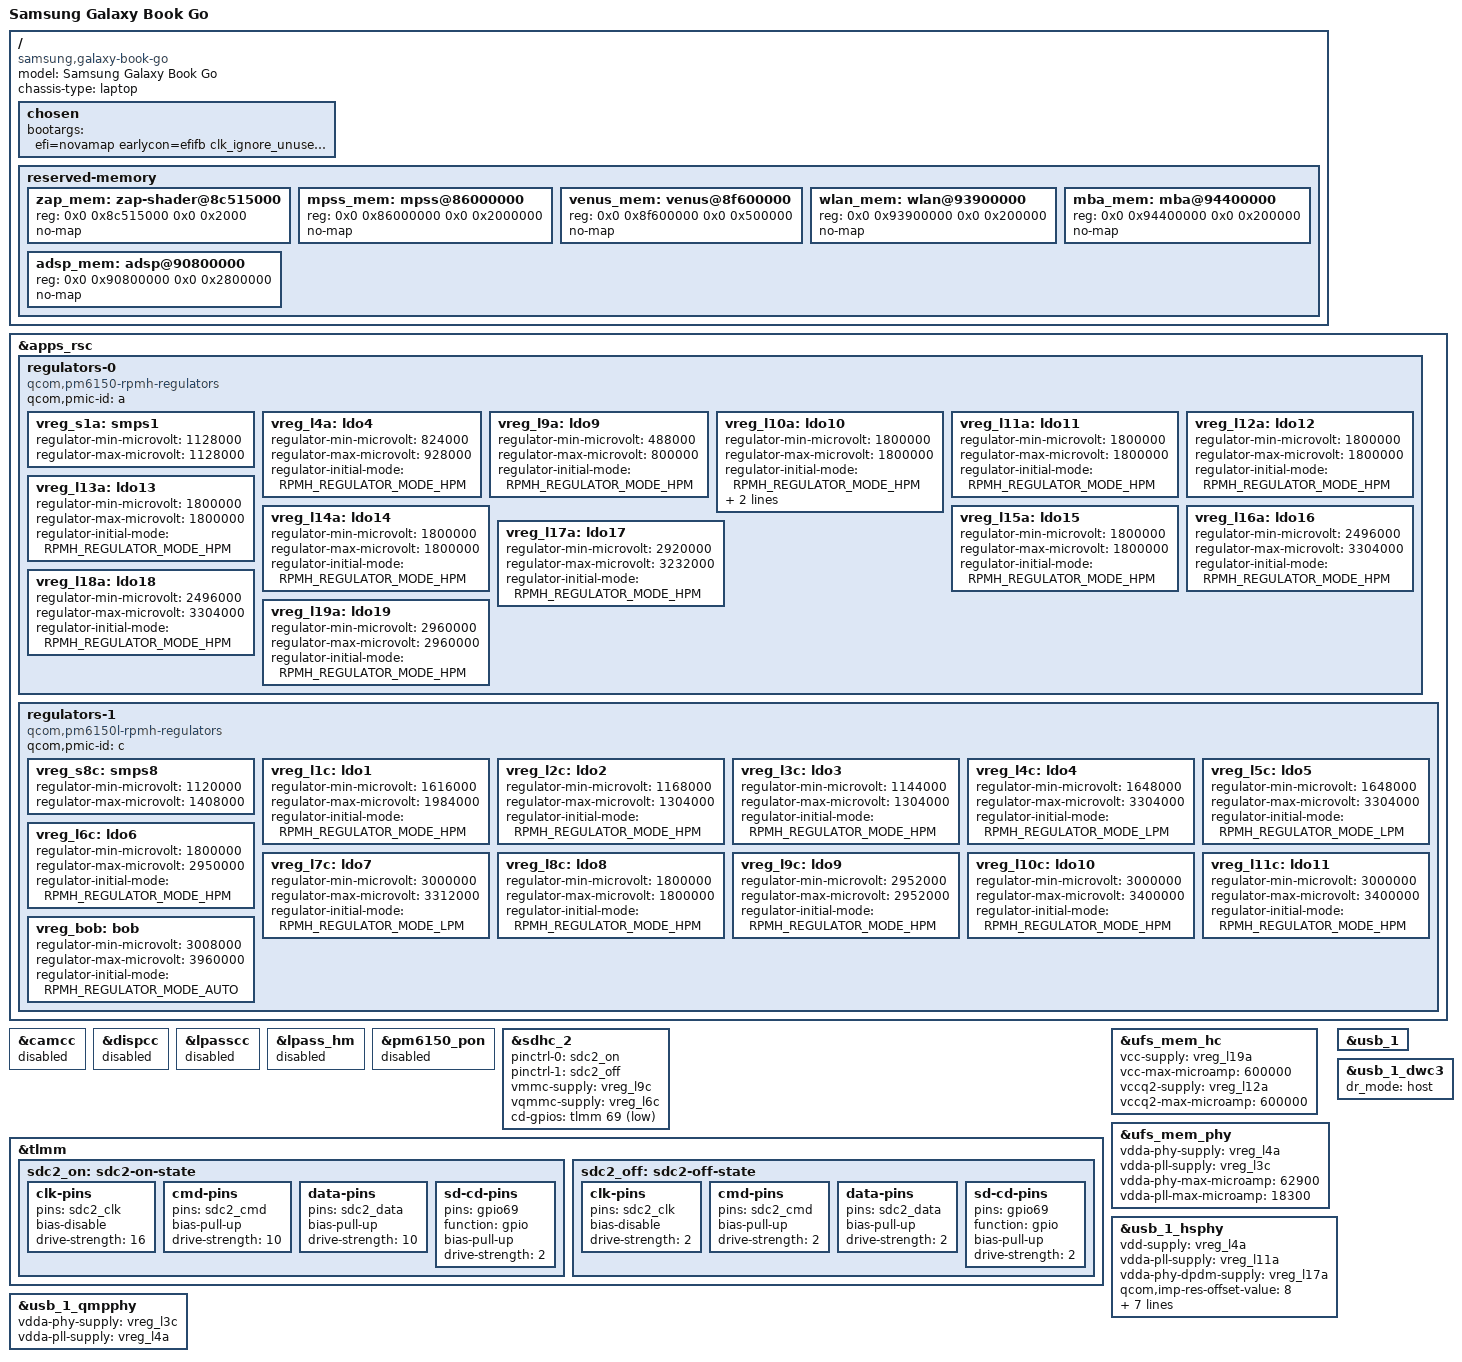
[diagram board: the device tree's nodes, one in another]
// SPDX-License-Identifier: BSD-3-Clause

/dts-v1/;

#include <dt-bindings/gpio/gpio.h>
#include <dt-bindings/regulator/qcom,rpmh-regulator.h>
#include "sc7180.dtsi"
#include "pm6150.dtsi"
#include "pm6150l.dtsi"

/ {
	model = "Samsung Galaxy Book Go";
	compatible = "samsung,galaxy-book-go", "qcom,sc7180";
	chassis-type = "laptop";

	chosen {
		bootargs = "efi=novamap earlycon=efifb clk_ignore_unused pd_ignore_unused console=efifb";
	};

	reserved-memory {
		zap_mem: zap-shader@8c515000 {
			reg = <0x0 0x8c515000 0x0 0x2000>;
			no-map;
		};

		mpss_mem: mpss@86000000 {
			reg = <0x0 0x86000000 0x0 0x2000000>;
			no-map;
		};

		venus_mem: venus@8f600000 {
			reg = <0x0 0x8f600000 0x0 0x500000>;
			no-map;
		};

		wlan_mem: wlan@93900000 {
			reg = <0x0 0x93900000 0x0 0x200000>;
			no-map;
		};

		mba_mem: mba@94400000 {
			reg = <0x0 0x94400000 0x0 0x200000>;
			no-map;
		};

		adsp_mem: adsp@90800000 {
			reg = <0x0 0x90800000 0x0 0x2800000>;
			no-map;
		};
	};
};

&apps_rsc {
	regulators-0 {
		compatible = "qcom,pm6150-rpmh-regulators";
		qcom,pmic-id = "a";

		vreg_s1a: smps1 {
			regulator-min-microvolt = <1128000>;
			regulator-max-microvolt = <1128000>;
		};

		vreg_l4a: ldo4 {
			regulator-min-microvolt = <824000>;
			regulator-max-microvolt = <928000>;
			regulator-initial-mode = <RPMH_REGULATOR_MODE_HPM>;
		};

		vreg_l9a: ldo9 {
			regulator-min-microvolt = <488000>;
			regulator-max-microvolt = <800000>;
			regulator-initial-mode = <RPMH_REGULATOR_MODE_HPM>;
		};

		vreg_l10a: ldo10 {
			regulator-min-microvolt = <1800000>;
			regulator-max-microvolt = <1800000>;
			regulator-initial-mode = <RPMH_REGULATOR_MODE_HPM>;

			regulator-always-on;
			regulator-boot-on;
		};

		vreg_l11a: ldo11 {
			regulator-min-microvolt = <1800000>;
			regulator-max-microvolt = <1800000>;
			regulator-initial-mode = <RPMH_REGULATOR_MODE_HPM>;
		};

		vreg_l12a: ldo12 {
			regulator-min-microvolt = <1800000>;
			regulator-max-microvolt = <1800000>;
			regulator-initial-mode = <RPMH_REGULATOR_MODE_HPM>;
		};

		vreg_l13a: ldo13 {
			regulator-min-microvolt = <1800000>;
			regulator-max-microvolt = <1800000>;
			regulator-initial-mode = <RPMH_REGULATOR_MODE_HPM>;
		};

		vreg_l14a: ldo14 {
			regulator-min-microvolt = <1800000>;
			regulator-max-microvolt = <1800000>;
			regulator-initial-mode = <RPMH_REGULATOR_MODE_HPM>;
		};

		vreg_l15a: ldo15 {
			regulator-min-microvolt = <1800000>;
			regulator-max-microvolt = <1800000>;
			regulator-initial-mode = <RPMH_REGULATOR_MODE_HPM>;
		};

		vreg_l16a: ldo16 {
			regulator-min-microvolt = <2496000>;
			regulator-max-microvolt = <3304000>;
			regulator-initial-mode = <RPMH_REGULATOR_MODE_HPM>;
		};

		vreg_l17a: ldo17 {
			regulator-min-microvolt = <2920000>;
			regulator-max-microvolt = <3232000>;
			regulator-initial-mode = <RPMH_REGULATOR_MODE_HPM>;
		};

		vreg_l18a: ldo18 {
			regulator-min-microvolt = <2496000>;
			regulator-max-microvolt = <3304000>;
			regulator-initial-mode = <RPMH_REGULATOR_MODE_HPM>;
		};

		vreg_l19a: ldo19 {
			regulator-min-microvolt = <2960000>;
			regulator-max-microvolt = <2960000>;
			regulator-initial-mode = <RPMH_REGULATOR_MODE_HPM>;
		};
	};

	regulators-1 {
		compatible = "qcom,pm6150l-rpmh-regulators";
		qcom,pmic-id = "c";

		vreg_s8c: smps8 {
			regulator-min-microvolt = <1120000>;
			regulator-max-microvolt = <1408000>;
		};

		vreg_l1c: ldo1 {
			regulator-min-microvolt = <1616000>;
			regulator-max-microvolt = <1984000>;
			regulator-initial-mode = <RPMH_REGULATOR_MODE_HPM>;
		};

		vreg_l2c: ldo2 {
			regulator-min-microvolt = <1168000>;
			regulator-max-microvolt = <1304000>;
			regulator-initial-mode = <RPMH_REGULATOR_MODE_HPM>;
		};

		vreg_l3c: ldo3 {
			regulator-min-microvolt = <1144000>;
			regulator-max-microvolt = <1304000>;
			regulator-initial-mode = <RPMH_REGULATOR_MODE_HPM>;
		};

		vreg_l4c: ldo4 {
			regulator-min-microvolt = <1648000>;
			regulator-max-microvolt = <3304000>;
			regulator-initial-mode = <RPMH_REGULATOR_MODE_LPM>;
		};

		vreg_l5c: ldo5 {
			regulator-min-microvolt = <1648000>;
			regulator-max-microvolt = <3304000>;
			regulator-initial-mode = <RPMH_REGULATOR_MODE_LPM>;
		};

		vreg_l6c: ldo6 {
			regulator-min-microvolt = <1800000>;
			regulator-max-microvolt = <2950000>;
			regulator-initial-mode = <RPMH_REGULATOR_MODE_HPM>;
		};

		vreg_l7c: ldo7 {
			regulator-min-microvolt = <3000000>;
			regulator-max-microvolt = <3312000>;
			regulator-initial-mode = <RPMH_REGULATOR_MODE_LPM>;
		};

		vreg_l8c: ldo8 {
			regulator-min-microvolt = <1800000>;
			regulator-max-microvolt = <1800000>;
			regulator-initial-mode = <RPMH_REGULATOR_MODE_HPM>;
		};

		vreg_l9c: ldo9 {
			regulator-min-microvolt = <2952000>;
			regulator-max-microvolt = <2952000>;
			regulator-initial-mode = <RPMH_REGULATOR_MODE_HPM>;
		};

		vreg_l10c: ldo10 {
			regulator-min-microvolt = <3000000>;
			regulator-max-microvolt = <3400000>;
			regulator-initial-mode = <RPMH_REGULATOR_MODE_HPM>;
		};

		vreg_l11c: ldo11 {
			regulator-min-microvolt = <3000000>;
			regulator-max-microvolt = <3400000>;
			regulator-initial-mode = <RPMH_REGULATOR_MODE_HPM>;
		};

		vreg_bob: bob {
			regulator-min-microvolt = <3008000>;
			regulator-max-microvolt = <3960000>;
			regulator-initial-mode = <RPMH_REGULATOR_MODE_AUTO>;
		};
	};
};

&camcc {
	status = "disabled";
};

&dispcc {
	status = "disabled";
};

&lpasscc {
	status = "disabled";
};

&lpass_hm {
	status = "disabled";
};

&pm6150_pon {
	status = "disabled";
};

&sdhc_2 {
	pinctrl-names = "default", "sleep";
	pinctrl-0 = <&sdc2_on>;
	pinctrl-1 = <&sdc2_off>;
	vmmc-supply = <&vreg_l9c>;
	vqmmc-supply = <&vreg_l6c>;
	cd-gpios = <&tlmm 69 GPIO_ACTIVE_LOW>;
	status = "okay";
};

&tlmm {
	sdc2_on: sdc2-on-state {
		clk-pins {
			pins = "sdc2_clk";
			bias-disable;
			drive-strength = <16>;
		};

		cmd-pins {
			pins = "sdc2_cmd";
			bias-pull-up;
			drive-strength = <10>;
		};

		data-pins {
			pins = "sdc2_data";
			bias-pull-up;
			drive-strength = <10>;
		};

		sd-cd-pins {
			pins = "gpio69";
			function = "gpio";
			bias-pull-up;
			drive-strength = <2>;
		};
	};

	sdc2_off: sdc2-off-state {
		clk-pins {
			pins = "sdc2_clk";
			bias-disable;
			drive-strength = <2>;
		};

		cmd-pins {
			pins = "sdc2_cmd";
			bias-pull-up;
			drive-strength = <2>;
		};

		data-pins {
			pins = "sdc2_data";
			bias-pull-up;
			drive-strength = <2>;
		};

		sd-cd-pins {
			pins = "gpio69";
			function = "gpio";
			bias-pull-up;
			drive-strength = <2>;
		};
	};
};

&ufs_mem_hc {
	vcc-supply = <&vreg_l19a>;
	vcc-max-microamp = <600000>;
	vccq2-supply = <&vreg_l12a>;
	vccq2-max-microamp = <600000>;
	status = "okay";
};

&ufs_mem_phy {
	vdda-phy-supply = <&vreg_l4a>;
	vdda-pll-supply = <&vreg_l3c>;
	vdda-phy-max-microamp = <62900>;
	vdda-pll-max-microamp = <18300>;
	status = "okay";
};

&usb_1 {
	status = "okay";
};

&usb_1_dwc3 {
	dr_mode = "host";
};

&usb_1_hsphy {
	vdd-supply = <&vreg_l4a>;
	vdda-pll-supply = <&vreg_l11a>;
	vdda-phy-dpdm-supply = <&vreg_l17a>;
	qcom,imp-res-offset-value = <8>;
	qcom,preemphasis-level = <QUSB2_V2_PREEMPHASIS_15_PERCENT>;
	qcom,preemphasis-width = <QUSB2_V2_PREEMPHASIS_WIDTH_HALF_BIT>;
	qcom,bias-ctrl-value = <0x22>;
	qcom,charge-ctrl-value = <3>;
	qcom,hsdisc-trim-value = <0>;
	status = "okay";
};

&usb_1_qmpphy {
	vdda-phy-supply = <&vreg_l3c>;
	vdda-pll-supply = <&vreg_l4a>;
	status = "okay";
};
